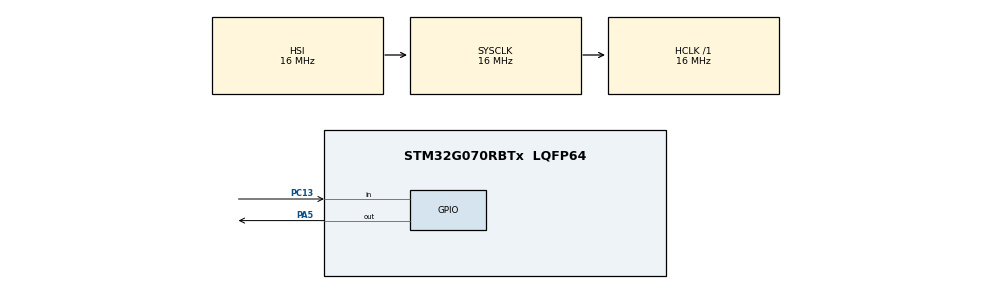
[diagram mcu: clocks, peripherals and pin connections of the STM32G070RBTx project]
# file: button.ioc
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Mcu.Family=STM32G0
Mcu.Name=STM32G070RBTx
Mcu.Package=LQFP64
PA5.Signal=GPIO_Output
PC13.Signal=GPIO_Input
ProjectManager.HeapSize=0x200
ProjectManager.StackSize=0x400
ProjectManager.TargetToolchain=EWARM V8.32
RCC.AHBFreq_Value=16000000
RCC.CortexFreq_Value=16000000
RCC.EXTERNAL_CLOCK_VALUE=48000
RCC.HCLKFreq_Value=16000000
RCC.HSE_VALUE=8000000
RCC.HSI_VALUE=16000000
RCC.LSE_VALUE=32768
RCC.SYSCLKFreq_VALUE=16000000
RCC.VCOOutputFreq_Value=128000000
VP_SYS_VS_DBSignals.Mode=DisableDeadBatterySignals
board=custom

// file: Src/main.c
/* USER CODE BEGIN Header */
/**
  ******************************************************************************
  * @file           : main.c
  * @brief          : Main program body
  ******************************************************************************
  * @attention
  *
  * <h2><center>&copy; Copyright (c) 2021 STMicroelectronics.
  * All rights reserved.</center></h2>
  *
  * This software component is licensed by ST under BSD 3-Clause license,
  * the "License"; You may not use this file except in compliance with the
  * License. You may obtain a copy of the License at:
  *                        opensource.org/licenses/BSD-3-Clause
  *
  ******************************************************************************
  */
/* USER CODE END Header */

#include "main.h"

/* USER CODE BEGIN Includes */
#include <stdio.h>
#include "bTest.h"

/* USER CODE END Includes */

/* USER CODE BEGIN PV */
//extern uint8_t tenMsFlag;

/* USER CODE END PV */

void SystemClock_Config(void);
static void MX_GPIO_Init(void);

int main(void)
{

  /* MCU Configuration--------------------------------------------------------*/

  /* Reset of all peripherals, Initializes the Flash interface and the Systick. */
  HAL_Init();

  /* USER CODE BEGIN Init */
  ButtonInit(GPIOC, GPIO_PIN_13);

  /* USER CODE END Init */

  /* Configure the system clock */
  SystemClock_Config();

  /* Initialize all configured peripherals */
  MX_GPIO_Init();

  /* Infinite loop */
  while (1)
  {

    /* USER CODE BEGIN 3 */
      PollKey();
  }
  /* USER CODE END 3 */
}

void SystemClock_Config(void)
{
  RCC_OscInitTypeDef RCC_OscInitStruct = {0};
  RCC_ClkInitTypeDef RCC_ClkInitStruct = {0};

  /** Configure the main internal regulator output voltage
  */
  HAL_PWREx_ControlVoltageScaling(PWR_REGULATOR_VOLTAGE_SCALE1);
  /** Initializes the CPU, AHB and APB busses clocks
  */
  RCC_OscInitStruct.OscillatorType = RCC_OSCILLATORTYPE_HSI;
  RCC_OscInitStruct.HSIState = RCC_HSI_ON;
  RCC_OscInitStruct.HSIDiv = RCC_HSI_DIV1;
  RCC_OscInitStruct.HSICalibrationValue = RCC_HSICALIBRATION_DEFAULT;
  RCC_OscInitStruct.PLL.PLLState = RCC_PLL_NONE;
  if (HAL_RCC_OscConfig(&RCC_OscInitStruct) != HAL_OK)
  {
    Error_Handler();
  }
  /** Initializes the CPU, AHB and APB busses clocks
  */
  RCC_ClkInitStruct.ClockType = RCC_CLOCKTYPE_HCLK|RCC_CLOCKTYPE_SYSCLK
                              |RCC_CLOCKTYPE_PCLK1;
  RCC_ClkInitStruct.SYSCLKSource = RCC_SYSCLKSOURCE_HSI;
  RCC_ClkInitStruct.AHBCLKDivider = RCC_SYSCLK_DIV1;
  RCC_ClkInitStruct.APB1CLKDivider = RCC_HCLK_DIV1;

  if (HAL_RCC_ClockConfig(&RCC_ClkInitStruct, FLASH_LATENCY_0) != HAL_OK)
  {
    Error_Handler();
  }
}

static void MX_GPIO_Init(void)
{
  GPIO_InitTypeDef GPIO_InitStruct = {0};

  /* GPIO Ports Clock Enable */
  __HAL_RCC_GPIOC_CLK_ENABLE();
  __HAL_RCC_GPIOA_CLK_ENABLE();

  /*Configure GPIO pin Output Level */
  HAL_GPIO_WritePin(GPIOA, GPIO_PIN_5, GPIO_PIN_RESET);

  /*Configure GPIO pin : PC13 */
  GPIO_InitStruct.Pin = GPIO_PIN_13;
  GPIO_InitStruct.Mode = GPIO_MODE_INPUT;
  GPIO_InitStruct.Pull = GPIO_NOPULL;
  HAL_GPIO_Init(GPIOC, &GPIO_InitStruct);

  /*Configure GPIO pin : PA5 */
  GPIO_InitStruct.Pin = GPIO_PIN_5;
  GPIO_InitStruct.Mode = GPIO_MODE_OUTPUT_PP;
  GPIO_InitStruct.Pull = GPIO_NOPULL;
  GPIO_InitStruct.Speed = GPIO_SPEED_FREQ_LOW;
  HAL_GPIO_Init(GPIOA, &GPIO_InitStruct);

}

void Error_Handler(void)
{
}

/************************ (C) COPYRIGHT STMicroelectronics *****END OF FILE****/
